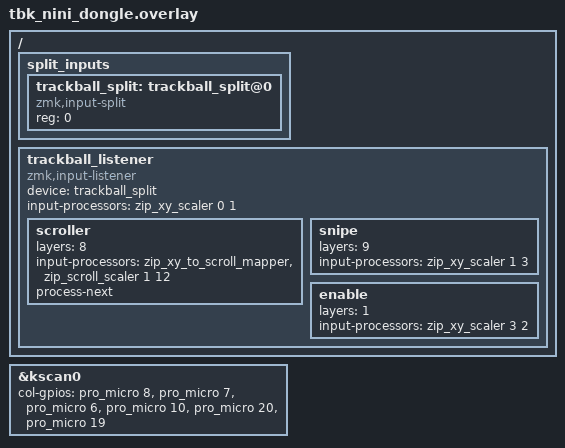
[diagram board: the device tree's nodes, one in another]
#include "tbk_nini.dtsi"

/ {
    split_inputs {
    #address-cells = <1>;
    #size-cells = <0>;

    trackball_split: trackball_split@0 {
      compatible = "zmk,input-split";
      reg = <0>;
    };
  };

    trackball_listener: trackball_listener {
      compatible = "zmk,input-listener";
      status = "okay";
      device = <&trackball_split>;
      // Input processors
      input-processors = <&zip_xy_scaler 0 1>;
      scroller {
        layers = <8>;
        input-processors = <&zip_xy_to_scroll_mapper>, <&zip_scroll_scaler 1 12>;
        process-next;
      };

      snipe {
        layers = <9>;
        input-processors = <&zip_xy_scaler 1 3>;
      };

      enable {
        layers = <1>;
        input-processors = <&zip_xy_scaler 3 2>;
      };
      // end of Input processors
    };

};

&kscan0 {
    col-gpios
      = <&pro_micro 8 GPIO_ACTIVE_HIGH>
      , <&pro_micro 7 GPIO_ACTIVE_HIGH>
      , <&pro_micro 6 GPIO_ACTIVE_HIGH>
      , <&pro_micro 10 GPIO_ACTIVE_HIGH>
      , <&pro_micro 20 GPIO_ACTIVE_HIGH>
      , <&pro_micro 19 GPIO_ACTIVE_HIGH>
      ;
};
